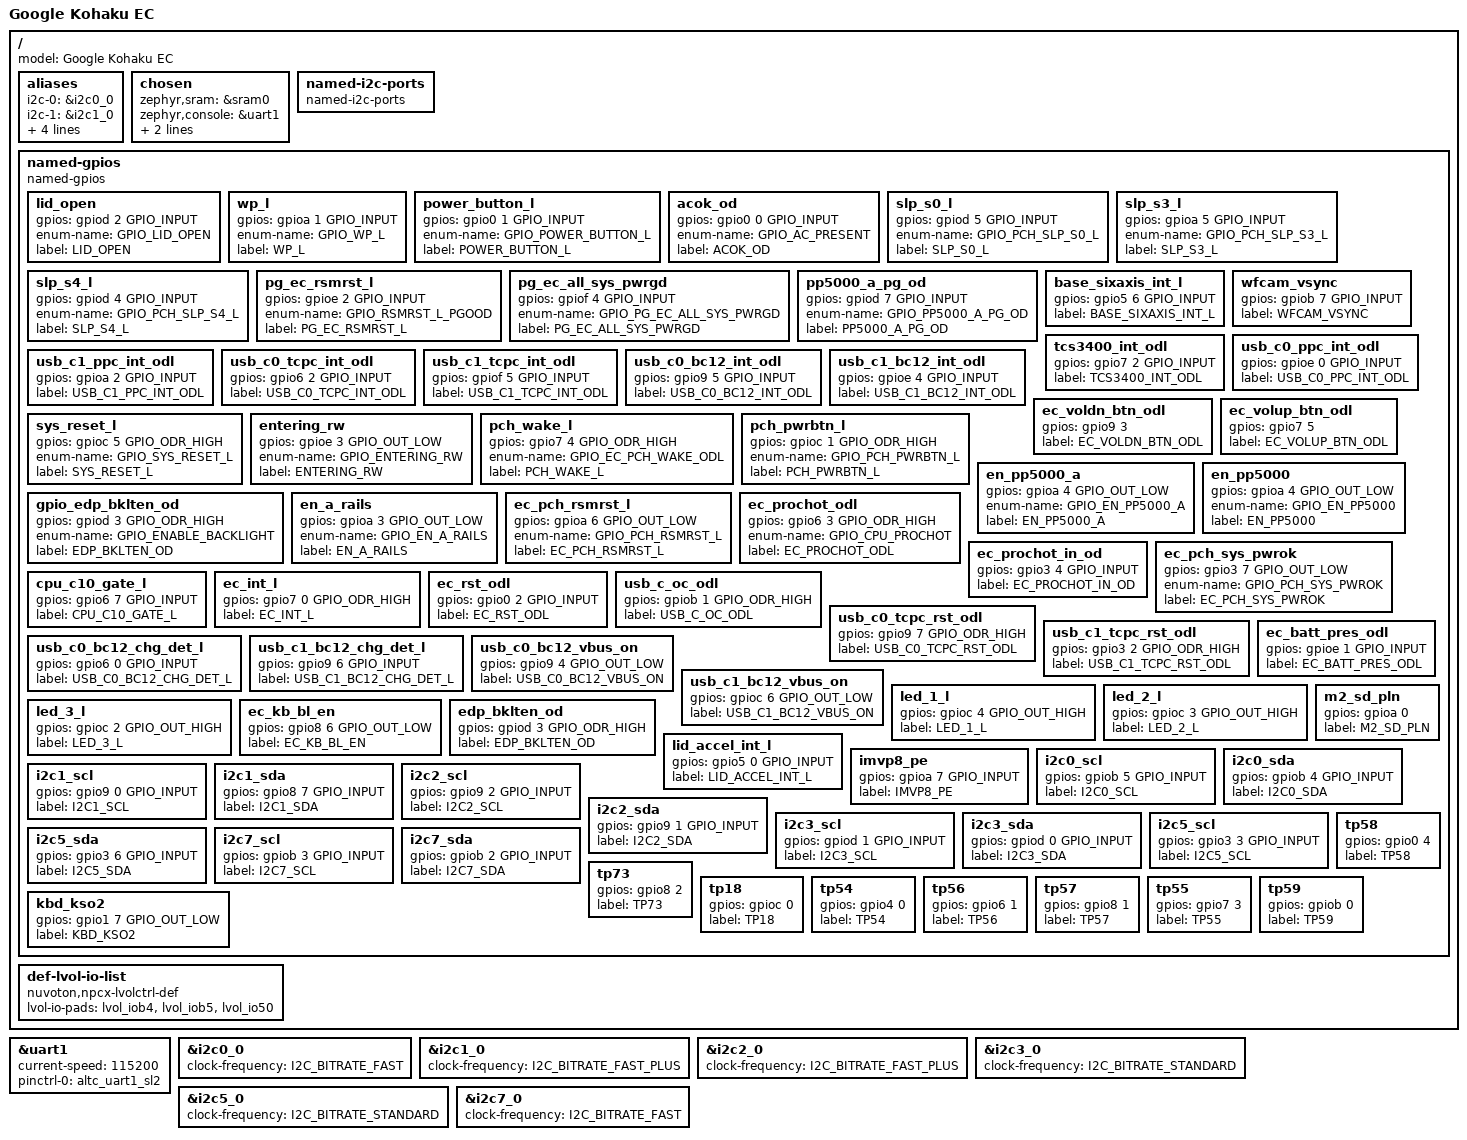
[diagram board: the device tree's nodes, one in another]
/* Copyright 2021 The Chromium OS Authors. All rights reserved.
 * Use of this source code is governed by a BSD-style license that can be
 * found in the LICENSE file.
 */

/dts-v1/;

#include <cros/nuvoton/npcx7.dtsi>
#include <dt-bindings/gpio_defines.h>
#include <nuvoton/npcx7m6fc.dtsi>

/ {
	model = "Google Kohaku EC";

	aliases {
		i2c-0 = &i2c0_0;
		i2c-1 = &i2c1_0;
		i2c-2 = &i2c2_0;
		i2c-3 = &i2c3_0;
		i2c-5 = &i2c5_0;
		i2c-7 = &i2c7_0;
	};

	chosen {
		zephyr,sram = &sram0;
		zephyr,console = &uart1;
		zephyr,shell-uart = &uart1;
		zephyr,flash = &flash0;
	};

	named-i2c-ports {
		compatible = "named-i2c-ports";
	};

	named-gpios {
		compatible = "named-gpios";

		lid_open {
			gpios = <&gpiod 2 GPIO_INPUT>;
			enum-name = "GPIO_LID_OPEN";
			label = "LID_OPEN";
		};
		wp_l {
			gpios = <&gpioa 1 GPIO_INPUT>;
			enum-name = "GPIO_WP_L";
			label = "WP_L";
		};
		power_button_l {
			gpios = <&gpio0 1 GPIO_INPUT>;
			enum-name = "GPIO_POWER_BUTTON_L";
			label = "POWER_BUTTON_L";
		};
		acok_od {
			gpios = <&gpio0 0 GPIO_INPUT>;
			enum-name = "GPIO_AC_PRESENT";
			label = "ACOK_OD";
		};
		slp_s0_l {
			gpios = <&gpiod 5 GPIO_INPUT>;
			enum-name = "GPIO_PCH_SLP_S0_L";
			label = "SLP_S0_L";
		};
		slp_s3_l {
			gpios = <&gpioa 5 GPIO_INPUT>;
			enum-name = "GPIO_PCH_SLP_S3_L";
			label = "SLP_S3_L";
		};
		slp_s4_l {
			gpios = <&gpiod 4 GPIO_INPUT>;
			enum-name = "GPIO_PCH_SLP_S4_L";
			label = "SLP_S4_L";
		};
		pg_ec_rsmrst_l {
			gpios = <&gpioe 2 GPIO_INPUT>;
			enum-name = "GPIO_RSMRST_L_PGOOD";
			label = "PG_EC_RSMRST_L";
		};
		pg_ec_all_sys_pwrgd {
			gpios = <&gpiof 4 GPIO_INPUT>;
			enum-name = "GPIO_PG_EC_ALL_SYS_PWRGD";
			label = "PG_EC_ALL_SYS_PWRGD";
		};
		pp5000_a_pg_od {
			gpios = <&gpiod 7 GPIO_INPUT>;
			enum-name = "GPIO_PP5000_A_PG_OD";
			label = "PP5000_A_PG_OD";
		};
		base_sixaxis_int_l {
			gpios = <&gpio5 6 GPIO_INPUT>;
			label = "BASE_SIXAXIS_INT_L";
		};
		wfcam_vsync {
			gpios = <&gpiob 7 GPIO_INPUT>;
			label = "WFCAM_VSYNC";
		};
		tcs3400_int_odl {
			gpios = <&gpio7 2 GPIO_INPUT>;
			label = "TCS3400_INT_ODL";
		};
		usb_c0_ppc_int_odl {
			gpios = <&gpioe 0 GPIO_INPUT>;
			label = "USB_C0_PPC_INT_ODL";
		};
		usb_c1_ppc_int_odl {
			gpios = <&gpioa 2 GPIO_INPUT>;
			label = "USB_C1_PPC_INT_ODL";
		};
		usb_c0_tcpc_int_odl {
			gpios = <&gpio6 2 GPIO_INPUT>;
			label = "USB_C0_TCPC_INT_ODL";
		};
		usb_c1_tcpc_int_odl {
			gpios = <&gpiof 5 GPIO_INPUT>;
			label = "USB_C1_TCPC_INT_ODL";
		};
		usb_c0_bc12_int_odl {
			gpios = <&gpio9 5 GPIO_INPUT>;
			label = "USB_C0_BC12_INT_ODL";
		};
		usb_c1_bc12_int_odl {
			gpios = <&gpioe 4 GPIO_INPUT>;
			label = "USB_C1_BC12_INT_ODL";
		};
		ec_voldn_btn_odl {
			gpios = <&gpio9 3 (GPIO_INPUT | GPIO_PULL_UP)>;
			label = "EC_VOLDN_BTN_ODL";
		};
		ec_volup_btn_odl {
			gpios = <&gpio7 5 (GPIO_INPUT | GPIO_PULL_UP)>;
			label = "EC_VOLUP_BTN_ODL";
		};
		sys_reset_l {
			gpios = <&gpioc 5 GPIO_ODR_HIGH>;
			enum-name = "GPIO_SYS_RESET_L";
			label = "SYS_RESET_L";
		};
		entering_rw {
			gpios = <&gpioe 3 GPIO_OUT_LOW>;
			enum-name = "GPIO_ENTERING_RW";
			label = "ENTERING_RW";
		};
		pch_wake_l {
			gpios = <&gpio7 4 GPIO_ODR_HIGH>;
			enum-name = "GPIO_EC_PCH_WAKE_ODL";
			label = "PCH_WAKE_L";
		};
		pch_pwrbtn_l {
			gpios = <&gpioc 1 GPIO_ODR_HIGH>;
			enum-name = "GPIO_PCH_PWRBTN_L";
			label = "PCH_PWRBTN_L";
		};
		en_pp5000_a {
			gpios = <&gpioa 4 GPIO_OUT_LOW>;
			enum-name = "GPIO_EN_PP5000_A";
			label = "EN_PP5000_A";
		};
		en_pp5000 {
			gpios = <&gpioa 4 GPIO_OUT_LOW>;
			enum-name = "GPIO_EN_PP5000";
			label = "EN_PP5000";
		};
		gpio_edp_bklten_od {
			gpios = <&gpiod 3 GPIO_ODR_HIGH>;
			enum-name = "GPIO_ENABLE_BACKLIGHT";
			label = "EDP_BKLTEN_OD";
		};
		en_a_rails {
			gpios = <&gpioa 3 GPIO_OUT_LOW>;
			enum-name = "GPIO_EN_A_RAILS";
			label = "EN_A_RAILS";
		};
		ec_pch_rsmrst_l {
			gpios = <&gpioa 6 GPIO_OUT_LOW>;
			enum-name = "GPIO_PCH_RSMRST_L";
			label = "EC_PCH_RSMRST_L";
		};
		ec_prochot_odl {
			gpios = <&gpio6 3 GPIO_ODR_HIGH>;
			enum-name = "GPIO_CPU_PROCHOT";
			label = "EC_PROCHOT_ODL";
		};
		ec_prochot_in_od {
			gpios = <&gpio3 4 GPIO_INPUT>;
			label = "EC_PROCHOT_IN_OD";
		};
		ec_pch_sys_pwrok {
			gpios = <&gpio3 7 GPIO_OUT_LOW>;
			enum-name = "GPIO_PCH_SYS_PWROK";
			label = "EC_PCH_SYS_PWROK";
		};
		cpu_c10_gate_l {
			gpios = <&gpio6 7 GPIO_INPUT>;
			label = "CPU_C10_GATE_L";
		};
		ec_int_l {
			gpios = <&gpio7 0 GPIO_ODR_HIGH>;
			label = "EC_INT_L";
		};
		ec_rst_odl {
			gpios = <&gpio0 2 GPIO_INPUT>;
			label = "EC_RST_ODL";
		};
		usb_c_oc_odl {
			gpios = <&gpiob 1 GPIO_ODR_HIGH>;
			label = "USB_C_OC_ODL";
		};
		usb_c0_tcpc_rst_odl {
			gpios = <&gpio9 7 GPIO_ODR_HIGH>;
			label = "USB_C0_TCPC_RST_ODL";
		};
		usb_c1_tcpc_rst_odl {
			gpios = <&gpio3 2 GPIO_ODR_HIGH>;
			label = "USB_C1_TCPC_RST_ODL";
		};
		usb_c0_bc12_chg_det_l {
			gpios = <&gpio6 0 GPIO_INPUT>;
			label = "USB_C0_BC12_CHG_DET_L";
		};
		usb_c1_bc12_chg_det_l {
			gpios = <&gpio9 6 GPIO_INPUT>;
			label = "USB_C1_BC12_CHG_DET_L";
		};
		usb_c0_bc12_vbus_on {
			gpios = <&gpio9 4 GPIO_OUT_LOW>;
			label = "USB_C0_BC12_VBUS_ON";
		};
		usb_c1_bc12_vbus_on {
			gpios = <&gpioc 6 GPIO_OUT_LOW>;
			label = "USB_C1_BC12_VBUS_ON";
		};
		ec_batt_pres_odl {
			gpios = <&gpioe 1 GPIO_INPUT>;
			label = "EC_BATT_PRES_ODL";
		};
		led_1_l {
			gpios = <&gpioc 4 GPIO_OUT_HIGH>;
			label = "LED_1_L";
		};
		led_2_l {
			gpios = <&gpioc 3 GPIO_OUT_HIGH>;
			label = "LED_2_L";
		};
		led_3_l {
			gpios = <&gpioc 2 GPIO_OUT_HIGH>;
			label = "LED_3_L";
		};
		ec_kb_bl_en {
			gpios = <&gpio8 6 GPIO_OUT_LOW>;
			label = "EC_KB_BL_EN";
		};
		edp_bklten_od {
			gpios = <&gpiod 3 GPIO_ODR_HIGH>;
			label = "EDP_BKLTEN_OD";
		};
		lid_accel_int_l {
			gpios = <&gpio5 0 GPIO_INPUT>;
			label = "LID_ACCEL_INT_L";
		};
		m2_sd_pln {
			gpios = <&gpioa 0 (GPIO_INPUT | GPIO_PULL_UP)>;
			label = "M2_SD_PLN";
		};
		imvp8_pe {
			gpios = <&gpioa 7 GPIO_INPUT>;
			label = "IMVP8_PE";
		};
		i2c0_scl {
			gpios = <&gpiob 5 GPIO_INPUT>;
			label = "I2C0_SCL";
		};
		i2c0_sda {
			gpios = <&gpiob 4 GPIO_INPUT>;
			label = "I2C0_SDA";
		};
		i2c1_scl {
			gpios = <&gpio9 0 GPIO_INPUT>;
			label = "I2C1_SCL";
		};
		i2c1_sda {
			gpios = <&gpio8 7 GPIO_INPUT>;
			label = "I2C1_SDA";
		};
		i2c2_scl {
			gpios = <&gpio9 2 GPIO_INPUT>;
			label = "I2C2_SCL";
		};
		i2c2_sda {
			gpios = <&gpio9 1 GPIO_INPUT>;
			label = "I2C2_SDA";
		};
		i2c3_scl {
			gpios = <&gpiod 1 GPIO_INPUT>;
			label = "I2C3_SCL";
		};
		i2c3_sda {
			gpios = <&gpiod 0 GPIO_INPUT>;
			label = "I2C3_SDA";
		};
		i2c5_scl {
			gpios = <&gpio3 3 GPIO_INPUT>;
			label = "I2C5_SCL";
		};
		i2c5_sda {
			gpios = <&gpio3 6 GPIO_INPUT>;
			label = "I2C5_SDA";
		};
		i2c7_scl {
			gpios = <&gpiob 3 GPIO_INPUT>;
			label = "I2C7_SCL";
		};
		i2c7_sda {
			gpios = <&gpiob 2 GPIO_INPUT>;
			label = "I2C7_SDA";
		};
		tp58 {
			gpios = <&gpio0 4 (GPIO_INPUT | GPIO_PULL_UP)>;
			label = "TP58";
		};
		tp73 {
			gpios = <&gpio8 2 (GPIO_INPUT | GPIO_PULL_UP)>;
			label = "TP73";
		};
		tp18 {
			gpios = <&gpioc 0 (GPIO_INPUT | GPIO_PULL_UP)>;
			label = "TP18";
		};
		tp54 {
			gpios = <&gpio4 0 (GPIO_INPUT | GPIO_PULL_UP)>;
			label = "TP54";
		};
		tp56 {
			gpios = <&gpio6 1 (GPIO_INPUT | GPIO_PULL_UP)>;
			label = "TP56";
		};
		tp57 {
			gpios = <&gpio8 1 (GPIO_INPUT | GPIO_PULL_UP)>;
			label = "TP57";
		};
		tp55 {
			gpios = <&gpio7 3 (GPIO_INPUT | GPIO_PULL_UP)>;
			label = "TP55";
		};
		tp59 {
			gpios = <&gpiob 0 (GPIO_INPUT | GPIO_PULL_UP)>;
			label = "TP59";
		};
		kbd_kso2 {
			gpios = <&gpio1 7 GPIO_OUT_LOW>;
			label = "KBD_KSO2";
		};
	};

	def-lvol-io-list {
		compatible = "nuvoton,npcx-lvolctrl-def";
		lvol-io-pads = <&lvol_iob4 &lvol_iob5 /* I2C_SDA0 & SCL0 */
		                &lvol_io50>;          /* GPIO50 */
	};
};

&uart1 {
	status = "okay";
	current-speed = <115200>;
	pinctrl-0 = <&altc_uart1_sl2>; /* Use UART1_SL2 ie. PIN64.65 */
};

&i2c0_0 {
	status = "okay";
	clock-frequency = <I2C_BITRATE_FAST>;
};

&i2c1_0 {
	status = "okay";
	clock-frequency = <I2C_BITRATE_FAST_PLUS>;
};

&i2c2_0 {
	status = "okay";
	clock-frequency = <I2C_BITRATE_FAST_PLUS>;
};

&i2c3_0 {
	status = "okay";
	clock-frequency = <I2C_BITRATE_STANDARD>;
};

&i2c5_0 {
	status = "okay";
	clock-frequency = <I2C_BITRATE_STANDARD>;
};

&i2c7_0 {
	status = "okay";
	clock-frequency = <I2C_BITRATE_FAST>;
};
